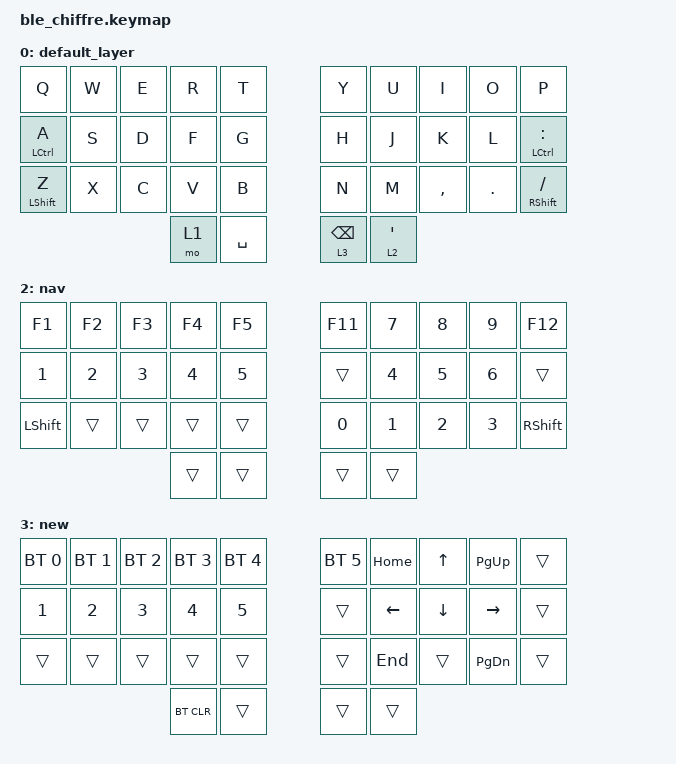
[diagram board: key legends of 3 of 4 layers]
/*
 * Copyright (c) 2020 The ZMK Contributors
 *
 * SPDX-License-Identifier: MIT
 */

#include <behaviors.dtsi>
#include <dt-bindings/zmk/keys.h>
#include <dt-bindings/zmk/bt.h>
#include <dt-bindings/zmk/rgb.h>

#define DEFAULT 0
#define NUM_SYM 1
#define NAV     2
#define NEW	3

/ {
	behaviors {
		rst: boot_reset 
		{
			compatible = "zmk,behavior-hold-tap";
			label = "Bootloader Tap - Reset Hold";
			#binding-cells = <2>;
			tapping_term_ms = <200>;
            flavor = "balanced";
			bindings = <&reset>, <&bootloader>;
        };

        bh: layer_taps 
		{
			compatible = "zmk,behavior-hold-tap";
			label = "Layer-Tap";
			#binding-cells = <2>;
			tapping_term_ms = <215>;
            flavor = "tap-preferred";
			bindings = <&mo>, <&kp>;
        };

        hm: homerow_mods0 
		{
			compatible = "zmk,behavior-hold-tap";
			label = "homerow mods";
			#binding-cells = <2>;
			tapping_term_ms = <230>;
            flavor = "tap-preferred";
			bindings = <&kp>, <&kp>;
        };
        
        hm1: homerow_mods1 
		{
			compatible = "zmk,behavior-hold-tap";
			label = "homerow mods";
			#binding-cells = <2>;
			tapping_term_ms = <205>;
            flavor = "tap-preferred";
			bindings = <&kp>, <&kp>;
        };

        hm2: homerow_mods2 
		{
			compatible = "zmk,behavior-hold-tap";
			label = "homerow mods 2";
			#binding-cells = <2>;
			tapping_term_ms = <250>;
            flavor = "tap-preferred";
			bindings = <&kp>, <&kp>;
        };

        com_col: comma_semicolon
		{
		 	compatible = "zmk,behavior-hold-tap";
	     	label = "Tap comma_hold colon";
			#binding-cells = <2>;
			tapping_term_ms = <150>;
            flavor = "balanced";
		 	bindings = <&kp>, <&kp>;
	    };
   	 };
};

/ {
	combos {
		compatible = "zmk,combos";
		combo_return {
			timeout-ms = <50>;
			key-positions = <17 18>;
			bindings = <&kp RET>;
		};
		combo_gesc 
		{
			timeout-ms = <30>;
			key-positions = <0 1>;
			bindings = <&com_col GRAVE ESC>;
		};
		combo_tab 
		{
			timeout-ms = <35>;
			key-positions = <11 12>;
			bindings = <&kp TAB>;
		};
		combo_mnxt 
		{
			timeout-ms = <30>;
			key-positions = <28 29>;
			bindings = <&kp C_NEXT>;
		};
		combo_mprev 
		{
			timeout-ms = <30>;
			key-positions = <27 28>;
			bindings = <&kp C_PREV>;	
		};
		combo_mpp 
		{
			timeout-ms = <30>;
			key-positions = <27 29>;
			bindings = <&kp C_PP>;
		};
		combo_del 
		{
			timeout-ms = <40>;
			key-positions = <7 8 9>;
			bindings = <&kp DEL>;
		};
	};
};

/ {
    keymap 
	{
    compatible = "zmk,keymap";

    default_layer {
            bindings = <
    &kp Q &kp W &kp E &kp R &kp T &kp Y &kp U &kp I &kp O &kp P
    &hm2 LCTRL A &kp S &kp D &kp F &kp G &kp H &kp J &kp K &kp L &hm2 LCTRL COLON
    &hm1 LSHFT Z &kp X &kp C &kp V &kp B &kp N &kp M &kp COMMA &kp DOT &hm RSHFT FSLH
    &mo 1 &kp SPACE &lt 3 BSPC &bh 2 APOS
            >;
        };

    num_sym {
            bindings = <
    &kp TILDE &trans &trans &trans &trans &trans &trans &trans &trans &kp MINUS   
    &kp EXCL &kp AT &kp POUND &kp DLLR &kp PRCNT &kp CARET &kp AMPS &kp ASTRK &kp LPAR &kp RPAR 
    &hm LSHFT EQUAL &trans &kp LBKT &kp RBKT &kp LGUI &trans &trans &trans &hm RSHFT BSLH
    &trans &trans &trans &kp CAPS
            >;
        };

    nav {
            bindings = <
    &kp F1    &kp F2     &kp F3     &kp F4    &kp F5    &kp F11   &kp N7    &kp N8   &kp N9   &kp F12   
    &kp N1    &kp N2     &kp N3     &kp N4    &kp N5    &trans    &kp N4    &kp N5   &kp N6   &trans 
    &kp LSHFT &trans     &trans     &trans    &trans    &kp N0    &kp N1    &kp N2   &kp N3   &kp RSHFT
    &trans &trans &trans &trans
            >;
        };

    new {
            bindings = <
    &bt BT_SEL 0 &bt BT_SEL 1 &bt BT_SEL 2 &bt BT_SEL 3 &bt BT_SEL 4 &bt BT_SEL 5 &kp HOME &kp UP &kp PG_UP &trans
    &kp N1 &kp N2 &kp N3 &kp N4 &kp N5 &trans &kp LEFT &kp DOWN &kp RIGHT &trans 
    &trans &trans &trans &trans &trans &trans &kp END  &trans   &kp PG_DN &trans
    &bt BT_CLR &trans &trans &trans
            >;
        };
    };
};

&lt {
    quick-tap-ms = <300>;
};
